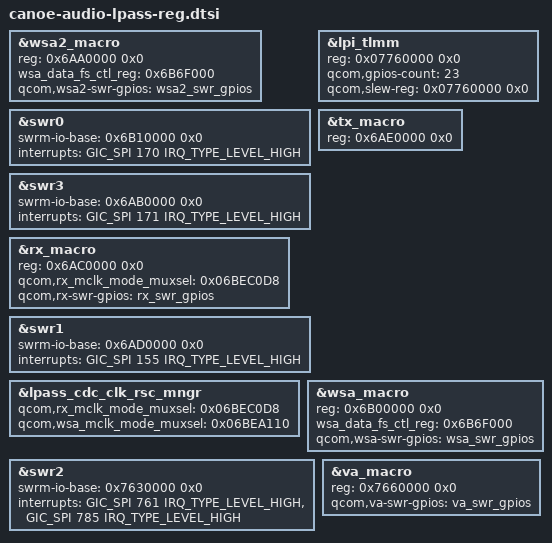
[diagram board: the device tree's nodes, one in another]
//
/* Copyright (c) Qualcomm Technologies, Inc. and/or its subsidiaries.
 *  SPDX-License-Identifier: BSD-3-Clause-Clear
 */

&wsa2_macro {
	reg = <0x6AA0000 0x0>;
	wsa_data_fs_ctl_reg = <0x6B6F000>;
	qcom,wsa2-swr-gpios = <&wsa2_swr_gpios>;
};

&swr0 {
	swrm-io-base = <0x6B10000 0x0>;
	interrupts = <GIC_SPI 170 IRQ_TYPE_LEVEL_HIGH>;
};

&swr3 {
	swrm-io-base = <0x6AB0000 0x0>;
	interrupts = <GIC_SPI 171 IRQ_TYPE_LEVEL_HIGH>;
};

&rx_macro {
	reg = <0x6AC0000 0x0>;
	qcom,rx_mclk_mode_muxsel = <0x06BEC0D8>;
	qcom,rx-swr-gpios = <&rx_swr_gpios>;
};

&lpi_tlmm {
	reg = <0x07760000 0x0>;
	qcom,gpios-count = <23>;
	qcom,slew-reg = <0x07760000 0x0>;

};

&swr1 {
	swrm-io-base = <0x6AD0000 0x0>;
	interrupts = <GIC_SPI 155 IRQ_TYPE_LEVEL_HIGH>;
};

&lpass_cdc_clk_rsc_mngr {
	qcom,rx_mclk_mode_muxsel = <0x06BEC0D8>;
	qcom,wsa_mclk_mode_muxsel = <0x06BEA110>;
};

&tx_macro {
	reg = <0x6AE0000 0x0>;
};

&wsa_macro {
	reg = <0x6B00000 0x0>;
	wsa_data_fs_ctl_reg = <0x6B6F000>;
	qcom,wsa-swr-gpios = <&wsa_swr_gpios>;
};

&swr2 {
	swrm-io-base = <0x7630000 0x0>;
	interrupts = <GIC_SPI 761 IRQ_TYPE_LEVEL_HIGH>,
	<GIC_SPI 785 IRQ_TYPE_LEVEL_HIGH>;
};

&va_macro {
	reg = <0x7660000 0x0>;
	qcom,va-swr-gpios = <&va_swr_gpios>;
};
